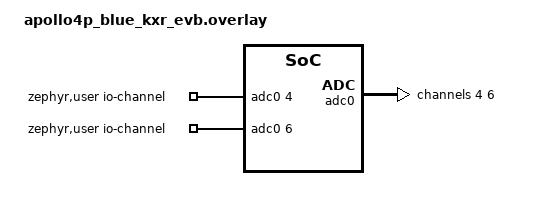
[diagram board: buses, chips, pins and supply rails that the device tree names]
/*
 * Copyright (c) 2025 Ambiq Micro Inc.
 *
 * SPDX-License-Identifier: Apache-2.0
 */
/ {
	zephyr,user {
		io-channels = <&adc0 4>, <&adc0 6>;
	};
};

&adc0 {
	status = "okay";
	interrupt-parent = <&nvic>;
	interrupts = <19 0>;
	#address-cells = <1>;
	#size-cells = <0>;

	channel@4 {
		reg = <4>;
		zephyr,gain = "ADC_GAIN_1";
		zephyr,reference = "ADC_REF_INTERNAL";
		zephyr,acquisition-time = <ADC_ACQ_TIME_DEFAULT>;
		zephyr,resolution = <12>;
	};

	channel@6 {
		reg = <6>;
		zephyr,gain = "ADC_GAIN_1";
		zephyr,reference = "ADC_REF_INTERNAL";
		zephyr,acquisition-time = <ADC_ACQ_TIME_DEFAULT>;
		zephyr,resolution = <12>;
	};
};
